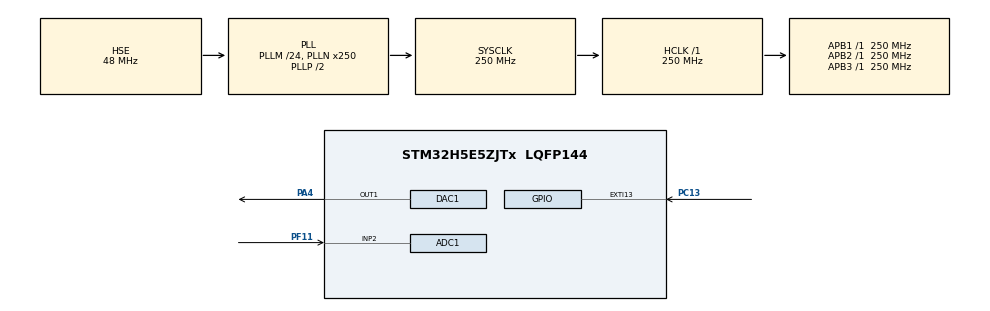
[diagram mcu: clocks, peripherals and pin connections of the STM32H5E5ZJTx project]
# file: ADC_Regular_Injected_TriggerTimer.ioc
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ADC1.Channel-0\#ChannelRegularConversion=ADC_CHANNEL_2
ADC1.ConversionDataManagement=ADC_CONVERSIONDATA_DMA_CIRCULAR
ADC1.DMAContinuousRequests=ENABLE
ADC1.EnableAnalogWatchDog1=false
ADC1.EnableInjectedConversion=ENABLE
ADC1.ExternalTrigConv=ADC_EXTERNALTRIG_T3_TRGO
ADC1.InjMonitoredBy-1\#ChannelInjectedConversion=__NULL
ADC1.InjNumberOfConversion=1
ADC1.InjectedChannel-1\#ChannelInjectedConversion=ADC_CHANNEL_VREFINT
ADC1.InjectedOffsetNumber-1\#ChannelInjectedConversion=ADC_OFFSET_NONE
ADC1.InjectedRank-1\#ChannelInjectedConversion=1
ADC1.InjectedSamplingTime-1\#ChannelInjectedConversion=ADC_SAMPLETIME_47CYCLES_5
ADC1.NbrOfConversionFlag=1
ADC1.Overrun=ADC_OVR_DATA_OVERWRITTEN
ADC1.SamplingTime-0\#ChannelRegularConversion=ADC_SAMPLETIME_247CYCLES_5
ADC1.master=1
BOOTPATH.BootPathName=LEGACY
BOOTPATH.UserSelectedBootPath=LEGACY
CORTEX_M33_NS.userName=CORTEX_M33
DAC1.DAC_Channel-DAC_OUT1=DAC_CHANNEL_1
DAC1.DAC_HighFrequency=DAC_HIGH_FREQUENCY_INTERFACE_MODE_ABOVE_160MHZ
DAC1.DAC_HoldTime-DAC_OUT1=10
DAC1.DAC_RefreshTime-DAC_OUT1=5
DAC1.DAC_SampleAndHold-DAC_OUT1=DAC_SAMPLEANDHOLD_ENABLE
DAC1.DAC_SampleTime-DAC_OUT1=20
GPDMA1.CIRCULARMODE_GPDMACH0=ENABLE
GPDMA1.DESTDATAWIDTH_GPDMACH0=DMA_DEST_DATAWIDTH_HALFWORD
GPDMA1.DESTINC_GPDMACH0=DMA_DINC_INCREMENTED
GPDMA1.IPHANDLE_GPDMACH0-SIMPLEREQUEST_GPDMACH0=__NULL
GPDMA1.PRIORITY_LL_CIRCULAR_GPDMACH0=DMA_LOW_PRIORITY_HIGH_WEIGHT
GPDMA1.REQUEST_GPDMACH0=GPDMA1_REQUEST_ADC1
GPDMA1.SRCDATAWIDTH_GPDMACH0=DMA_SRC_DATAWIDTH_HALFWORD
Mcu.Family=STM32H5
Mcu.Name=STM32H5E5ZJTx
Mcu.Package=LQFP144
NVIC.ADC1_IRQn=true\:0\:0\:false\:false\:true\:true\:true\:true
NVIC.EXTI13_IRQn=true\:0\:0\:false\:false\:true\:true\:true\:true
NVIC.GPDMA1_Channel0_IRQn=true\:0\:0\:false\:false\:true\:false\:true\:true
NVIC.PriorityGroup=NVIC_PRIORITYGROUP_4
PA4.Signal=COMP_DAC11_group
PC13.Signal=GPXTI13
PF11.Mode=IN2-Single-Ended
PF11.Signal=ADC1_INP2
PH0-OSC_IN(PH0).Mode=HSE-External-Oscillator
PH0-OSC_IN(PH0).Signal=RCC_OSC_IN
PH1-OSC_OUT(PH1).Mode=HSE-External-Oscillator
PH1-OSC_OUT(PH1).Signal=RCC_OSC_OUT
ProjectManager.HeapSize=0x200
ProjectManager.StackSize=0x400
ProjectManager.TargetToolchain=EWARM V9.20
RCC.ADCCLKDivider=RCC_ADC_DIV2
RCC.ADCCLockSelection=RCC_ADCDACCLKSOURCE_HSI
RCC.ADCFreq_Value=16000000
RCC.AHBFreq_Value=250000000
RCC.APB1Freq_Value=250000000
RCC.APB1TimFreq_Value=250000000
RCC.APB2Freq_Value=250000000
RCC.APB2TimFreq_Value=250000000
RCC.APB3Freq_Value=250000000
RCC.CSI_VALUE=4000000
RCC.CortexFreq_Value=250000000
RCC.DACLowPowerCLockSelection=RCC_DACLPCLKSOURCE_LSI
RCC.EPOD_VALUE=48000000
RCC.HCLKFreq_Value=250000000
RCC.HSE_VALUE=48000000
RCC.HSI48_VALUE=48000000
RCC.HSI_VALUE=64000000
RCC.LSE_VALUE=32768
RCC.LSIRC_VALUE=32000
RCC.PLLFRACN=0
RCC.PLLM=24
RCC.PLLN=250
RCC.PLLSourceVirtual=RCC_PLL1_SOURCE_HSE
RCC.SYSCLKFreq_VALUE=250000000
RCC.SYSCLKSource=RCC_SYSCLKSOURCE_PLLCLK
RCC.USBFreq_Value=258000000
RCC.VCOOutputFreq_Value=500000000
SH.COMP_DAC11_group.0=DAC1_OUT1,DAC_OUT1
TIM3.PeriodNoDither=PERIOD_VALUE
TIM3.Prescaler=PRESCALER_VALUE
TIM3.TIM_MasterOutputTrigger=TIM_TRGO_UPDATE
VP_ADC1_Vref_Input.Mode=IN-Vrefint
VP_BOOTPATH_VS_BOOTPATH.Mode=BP_Activate
VP_CORTEX_M33_NS_VS_Hclk.Mode=Hclk_Mode
VP_GPDMA1_VS_GPDMACH0.Mode=SIMPLEREQUEST_GPDMACH0
VP_ICACHE_VS_ICACHE.Mode=DefaultMode
VP_PWR_VS_LPOM.Mode=PowerOptimisation
VP_PWR_VS_SECSignals.Mode=Security/Privilege
VP_TIM3_VS_ClockSourceINT.Mode=Internal
board=custom

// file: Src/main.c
/* USER CODE BEGIN Header */
/**
  ******************************************************************************
  * @file           : main.c
  * @brief          : Main program body
  ******************************************************************************
  * @attention
  *
  * Copyright (c) 2025 STMicroelectronics.
  * All rights reserved.
  *
  * This software is licensed under terms that can be found in the LICENSE file
  * in the root directory of this software component.
  * If no LICENSE file comes with this software, it is provided AS-IS.
  *
  ******************************************************************************
  */
/* USER CODE END Header */
#include "main.h"

/* USER CODE BEGIN PD */
#define RANGE_12BITS                   ((uint32_t) 4095)    /* Max digital value with a full range of 12 bits */

/* ADC parameters */
#define ADCCONVERTEDVALUES_BUFFER_SIZE ((uint32_t)   32)    /* Size of array containing ADC converted values, aligned on cache line size */
/* USER CODE END PD */

ADC_HandleTypeDef hadc1;
DMA_NodeTypeDef Node_GPDMA1_Channel0;
DMA_QListTypeDef List_GPDMA1_Channel0;
DMA_HandleTypeDef handle_GPDMA1_Channel0;

DAC_HandleTypeDef hdac1;

TIM_HandleTypeDef htim3;

/* USER CODE BEGIN PV */

/* Variable containing ADC conversions results */
ALIGN_32BYTES(__IO uint16_t   aADCxConvertedValues[ADCCONVERTEDVALUES_BUFFER_SIZE]); /* ADC conversion results table of regular group, channel on rank1 */
__IO uint16_t   uhADCxConvertedValue_Injected;                        /* ADC conversion result of injected group, channel on rank1 */

uint16_t        uhADCxConvertedValue_Regular_Avg_half1;  /* Average of the 1st half of ADC conversion results table of regular group, channel on rank1 */
uint16_t        uhADCxConvertedValue_Regular_Avg_half2;  /* Average of the 2nd half of ADC conversion results table of regular group, channel on rank1 */
uint16_t*       puhADCxConvertedValue_Regular_Avg;       /* Pointer to the average of the 1st or 2nd half of ADC conversion results table of regular group, channel on rank1 */

/* Variables to manage push button on board: interface between ExtLine interruption and main program */
__IO uint8_t    ubUserButtonClickEvent = RESET;  /* Event detection: Set after User Button interrupt */

/* USER CODE END PV */

void SystemClock_Config(void);
static void MX_GPIO_Init(void);
static void MX_GPDMA1_Init(void);
static void MX_ICACHE_Init(void);
static void MX_ADC1_Init(void);
static void MX_TIM3_Init(void);
static void MX_DAC1_Init(void);
/* USER CODE BEGIN PFP */
static void WaveformVoltageGenerationForTest_Config(void);
static void WaveformVoltageGenerationForTest_Update(void);
/* USER CODE END PFP */

int main(void)
{

  /* MCU Configuration--------------------------------------------------------*/

  /* Reset of all peripherals, Initializes the Flash interface and the Systick. */
  HAL_Init();

  /* Configure the system clock */
  SystemClock_Config();

  /* USER CODE BEGIN SysInit */
  /* Initialize LED on board */
  BSP_LED_Init(LED_GREEN);
  BSP_LED_Init(LED_RED);

  /* USER CODE END SysInit */

  /* Initialize all configured peripherals */
  MX_GPIO_Init();
  MX_GPDMA1_Init();
  MX_ICACHE_Init();
  MX_ADC1_Init();
  MX_TIM3_Init();
  MX_DAC1_Init();
  /* USER CODE BEGIN 2 */

  /* Perform ADC calibration */
  if (HAL_ADCEx_Calibration_Start(&hadc1, ADC_SINGLE_ENDED) != HAL_OK)
  {
    /* Calibration Error */
    Error_Handler();
  }

  /* WAVEFORM_VOLTAGE_GENERATION_FOR_TEST */

  WaveformVoltageGenerationForTest_Config();

  /* Timer enable */
  if (HAL_TIM_Base_Start(&htim3) != HAL_OK)
  {
    /* Counter Enable Error */
    Error_Handler();
  }

    /*## Start ADC conversions #################################################*/

  /* Start ADC conversion on regular group with transfer by DMA */
  if (HAL_ADC_Start_DMA(&hadc1,
                        (uint32_t *)aADCxConvertedValues,
                        ADCCONVERTEDVALUES_BUFFER_SIZE
                       ) != HAL_OK)
  {
    /* Start Error */
    Error_Handler();
  }

  /* USER CODE END 2 */

  /* Infinite loop */
  /* USER CODE BEGIN WHILE */
  while (1)
  {
    /* Wait for event on push button to perform following actions */
    while ((ubUserButtonClickEvent) == RESET)
    {
    }
    /* Reset variable for next loop iteration */
    ubUserButtonClickEvent = RESET;

    /* Start ADC conversion on injected group */
    if (HAL_ADCEx_InjectedStart_IT(&hadc1) != HAL_OK)
    {
      /* Start Conversation Error */
      Error_Handler();
    }

    /* Modifies the voltage level incrementally from 0V to Vdda at each call. */
    /* Circular waveform of ramp: When the maximum level is reaches,          */
    /* restart from 0V.                                                       */
    WaveformVoltageGenerationForTest_Update();

    /* Wait for acquisition time of ADC samples on regular and injected       */
    /* groups:                                                                */
    /* wait time to let a full 1/2 buffer of regular group to be filled with  */
    /* new conversion values (in ms)      */
    HAL_Delay(100);

    /* Turn-on/off LED_GREEN in function of ADC conversion result */
    /* - Turn-off if voltage measured by injected group is below voltage      */
    /*   measured by regular group (average of results table)                 */
    /* - Turn-off if voltage measured by injected group is above voltage      */
    /*   measured by regular group (average of results table)                 */

    /* Variables of conversions results are updated into ADC conversions      */
    /* interrupt callback.                                                    */

    if (uhADCxConvertedValue_Injected < *puhADCxConvertedValue_Regular_Avg)
    {
      BSP_LED_Off(LED_GREEN);
    }
    else
    {
      BSP_LED_On(LED_GREEN);
    }

    /* USER CODE END WHILE */

  }
}

void SystemClock_Config(void)
{
  RCC_OscInitTypeDef RCC_OscInitStruct = {0};
  RCC_ClkInitTypeDef RCC_ClkInitStruct = {0};

  /** Configure the main internal regulator output voltage
  */
  __HAL_PWR_VOLTAGESCALING_CONFIG(PWR_REGULATOR_VOLTAGE_SCALE0);

  while(!__HAL_PWR_GET_FLAG(PWR_FLAG_VOSRDY)) {}

  /** Initializes the RCC Oscillators according to the specified parameters
  * in the RCC_OscInitTypeDef structure.
  */
  RCC_OscInitStruct.OscillatorType = RCC_OSCILLATORTYPE_HSI|RCC_OSCILLATORTYPE_LSI
                              |RCC_OSCILLATORTYPE_HSE;
  RCC_OscInitStruct.HSEState = RCC_HSE_ON;
  RCC_OscInitStruct.HSIState = RCC_HSI_ON;
  RCC_OscInitStruct.HSIDiv = RCC_HSI_DIV2;
  RCC_OscInitStruct.HSICalibrationValue = RCC_HSICALIBRATION_DEFAULT;
  RCC_OscInitStruct.LSIState = RCC_LSI_ON;
  RCC_OscInitStruct.PLL.PLLState = RCC_PLL_ON;
  RCC_OscInitStruct.PLL.PLLSource = RCC_PLL1_SOURCE_HSE;
  RCC_OscInitStruct.PLL.PLLM = 24;
  RCC_OscInitStruct.PLL.PLLN = 250;
  RCC_OscInitStruct.PLL.PLLP = 2;
  RCC_OscInitStruct.PLL.PLLQ = 2;
  RCC_OscInitStruct.PLL.PLLR = 2;
  RCC_OscInitStruct.PLL.PLLRGE = RCC_PLL1_VCIRANGE_1;
  RCC_OscInitStruct.PLL.PLLVCOSEL = RCC_PLL1_VCORANGE_WIDE;
  RCC_OscInitStruct.PLL.PLLFRACN = 0;
  if (HAL_RCC_OscConfig(&RCC_OscInitStruct) != HAL_OK)
  {
    Error_Handler();
  }

  /** Initializes the CPU, AHB and APB buses clocks
  */
  RCC_ClkInitStruct.ClockType = RCC_CLOCKTYPE_HCLK|RCC_CLOCKTYPE_SYSCLK
                              |RCC_CLOCKTYPE_PCLK1|RCC_CLOCKTYPE_PCLK2
                              |RCC_CLOCKTYPE_PCLK3;
  RCC_ClkInitStruct.SYSCLKSource = RCC_SYSCLKSOURCE_PLLCLK;
  RCC_ClkInitStruct.AHBCLKDivider = RCC_SYSCLK_DIV1;
  RCC_ClkInitStruct.APB1CLKDivider = RCC_HCLK_DIV1;
  RCC_ClkInitStruct.APB2CLKDivider = RCC_HCLK_DIV1;
  RCC_ClkInitStruct.APB3CLKDivider = RCC_HCLK_DIV1;

  if (HAL_RCC_ClockConfig(&RCC_ClkInitStruct, FLASH_LATENCY_5) != HAL_OK)
  {
    Error_Handler();
  }

  /** Configure the programming delay
  */
  __HAL_FLASH_SET_PROGRAM_DELAY(FLASH_PROGRAMMING_DELAY_2);
}

static void MX_ADC1_Init(void)
{

  ADC_ChannelConfTypeDef sConfig = {0};
  ADC_InjectionConfTypeDef sConfigInjected = {0};

  /** Common config
  */
  hadc1.Instance = ADC1;
  hadc1.Init.ClockPrescaler = ADC_CLOCK_ASYNC_DIV1;
  hadc1.Init.Resolution = ADC_RESOLUTION_12B;
  hadc1.Init.DataAlign = ADC_DATAALIGN_RIGHT;
  hadc1.Init.ScanConvMode = ADC_SCAN_DISABLE;
  hadc1.Init.EOCSelection = ADC_EOC_SINGLE_CONV;
  hadc1.Init.LowPowerAutoWait = DISABLE;
  hadc1.Init.ContinuousConvMode = DISABLE;
  hadc1.Init.NbrOfConversion = 1;
  hadc1.Init.DiscontinuousConvMode = DISABLE;
  hadc1.Init.ExternalTrigConv = ADC_EXTERNALTRIG_T3_TRGO;
  hadc1.Init.ExternalTrigConvEdge = ADC_EXTERNALTRIGCONVEDGE_RISING;
  hadc1.Init.DMAContinuousRequests = ENABLE;
  hadc1.Init.SamplingMode = ADC_SAMPLING_MODE_NORMAL;
  hadc1.Init.Overrun = ADC_OVR_DATA_OVERWRITTEN;
  hadc1.Init.OversamplingMode = DISABLE;
  if (HAL_ADC_Init(&hadc1) != HAL_OK)
  {
    Error_Handler();
  }

  /** Disable Injected Queue
  */
  HAL_ADCEx_DisableInjectedQueue(&hadc1);

  /** Configure Regular Channel
  */
  sConfig.Channel = ADC_CHANNEL_2;
  sConfig.Rank = ADC_REGULAR_RANK_1;
  sConfig.SamplingTime = ADC_SAMPLETIME_247CYCLES_5;
  sConfig.SingleDiff = ADC_SINGLE_ENDED;
  sConfig.OffsetNumber = ADC_OFFSET_NONE;
  sConfig.Offset = 0;
  if (HAL_ADC_ConfigChannel(&hadc1, &sConfig) != HAL_OK)
  {
    Error_Handler();
  }

  /** Configure Injected Channel
  */
  sConfigInjected.InjectedChannel = ADC_CHANNEL_VREFINT;
  sConfigInjected.InjectedRank = ADC_INJECTED_RANK_1;
  sConfigInjected.InjectedSamplingTime = ADC_SAMPLETIME_47CYCLES_5;
  sConfigInjected.InjectedSingleDiff = ADC_SINGLE_ENDED;
  sConfigInjected.InjectedOffsetNumber = ADC_OFFSET_NONE;
  sConfigInjected.InjectedOffset = 0;
  sConfigInjected.InjectedNbrOfConversion = 1;
  sConfigInjected.InjectedDiscontinuousConvMode = DISABLE;
  sConfigInjected.AutoInjectedConv = DISABLE;
  sConfigInjected.QueueInjectedContext = DISABLE;
  sConfigInjected.ExternalTrigInjecConv = ADC_INJECTED_SOFTWARE_START;
  sConfigInjected.ExternalTrigInjecConvEdge = ADC_EXTERNALTRIGINJECCONV_EDGE_NONE;
  sConfigInjected.InjecOversamplingMode = DISABLE;
  if (HAL_ADCEx_InjectedConfigChannel(&hadc1, &sConfigInjected) != HAL_OK)
  {
    Error_Handler();
  }

}

static void MX_DAC1_Init(void)
{

  DAC_ChannelConfTypeDef sConfig = {0};

  /** DAC Initialization
  */
  hdac1.Instance = DAC1;
  if (HAL_DAC_Init(&hdac1) != HAL_OK)
  {
    Error_Handler();
  }

  /** DAC channel OUT1 config
  */
  sConfig.DAC_HighFrequency = DAC_HIGH_FREQUENCY_INTERFACE_MODE_ABOVE_160MHZ;
  sConfig.DAC_DMADoubleDataMode = DISABLE;
  sConfig.DAC_SignedFormat = DISABLE;
  sConfig.DAC_SampleAndHold = DAC_SAMPLEANDHOLD_ENABLE;
  sConfig.DAC_Trigger = DAC_TRIGGER_NONE;
  sConfig.DAC_OutputBuffer = DAC_OUTPUTBUFFER_ENABLE;
  sConfig.DAC_ConnectOnChipPeripheral = DAC_CHIPCONNECT_EXTERNAL;
  sConfig.DAC_UserTrimming = DAC_TRIMMING_FACTORY;
  sConfig.DAC_SampleAndHoldConfig.DAC_SampleTime = 20;
  sConfig.DAC_SampleAndHoldConfig.DAC_HoldTime = 10;
  sConfig.DAC_SampleAndHoldConfig.DAC_RefreshTime = 5;
  if (HAL_DAC_ConfigChannel(&hdac1, &sConfig, DAC_CHANNEL_1) != HAL_OK)
  {
    Error_Handler();
  }

}

static void MX_GPDMA1_Init(void)
{

  /* Peripheral clock enable */
  __HAL_RCC_GPDMA1_CLK_ENABLE();

  /* GPDMA1 interrupt Init */
    HAL_NVIC_SetPriority(GPDMA1_Channel0_IRQn, 0, 0);
    HAL_NVIC_EnableIRQ(GPDMA1_Channel0_IRQn);

}

static void MX_ICACHE_Init(void)
{

  /** Enable instruction cache (default 2-ways set associative cache)
  */
  if (HAL_ICACHE_Enable() != HAL_OK)
  {
    Error_Handler();
  }

}

static void MX_TIM3_Init(void)
{

  TIM_ClockConfigTypeDef sClockSourceConfig = {0};
  TIM_MasterConfigTypeDef sMasterConfig = {0};

  htim3.Instance = TIM3;
  htim3.Init.Prescaler = PRESCALER_VALUE;
  htim3.Init.CounterMode = TIM_COUNTERMODE_UP;
  htim3.Init.Period = PERIOD_VALUE;
  htim3.Init.ClockDivision = TIM_CLOCKDIVISION_DIV1;
  htim3.Init.AutoReloadPreload = TIM_AUTORELOAD_PRELOAD_DISABLE;
  if (HAL_TIM_Base_Init(&htim3) != HAL_OK)
  {
    Error_Handler();
  }
  sClockSourceConfig.ClockSource = TIM_CLOCKSOURCE_INTERNAL;
  if (HAL_TIM_ConfigClockSource(&htim3, &sClockSourceConfig) != HAL_OK)
  {
    Error_Handler();
  }
  sMasterConfig.MasterOutputTrigger = TIM_TRGO_UPDATE;
  sMasterConfig.MasterSlaveMode = TIM_MASTERSLAVEMODE_DISABLE;
  if (HAL_TIMEx_MasterConfigSynchronization(&htim3, &sMasterConfig) != HAL_OK)
  {
    Error_Handler();
  }

}

static void MX_GPIO_Init(void)
{
  GPIO_InitTypeDef GPIO_InitStruct = {0};

  /* GPIO Ports Clock Enable */
  __HAL_RCC_GPIOC_CLK_ENABLE();
  __HAL_RCC_GPIOH_CLK_ENABLE();

  /*Configure GPIO pin : PC13 */
  GPIO_InitStruct.Pin = GPIO_PIN_13;
  GPIO_InitStruct.Mode = GPIO_MODE_IT_RISING;
  GPIO_InitStruct.Pull = GPIO_NOPULL;
  HAL_GPIO_Init(GPIOC, &GPIO_InitStruct);

  /* EXTI interrupt init*/
  HAL_NVIC_SetPriority(EXTI13_IRQn, 0, 0);
  HAL_NVIC_EnableIRQ(EXTI13_IRQn);

}

/* USER CODE BEGIN 4 */

/**
  * @brief  For this example, generate a waveform voltage on a spare DAC
  *         channel, so user has just to connect a wire between DAC channel
  *         (pin PA.04) and ADC channel (pin PF.11) to run this example.
  *         (this prevents the user from resorting to an external signal generator)
  *         This function configures the DAC and generates a constant voltage of Vdda/2.
  *         To modify the voltage level, use function "WaveformVoltageGenerationForTest_Update"
  * @param  None
  * @retval None
  */
static void WaveformVoltageGenerationForTest_Config(void)
{

  /*## Enable peripherals ####################################################*/

  /* Set DAC Channel data register: channel corresponding to ADC channel CHANNELa */
  /* Set DAC output to 1/2 of full range (4095 <=> Vdda=3.3V): 2048 <=> 1.65V */
  if (HAL_DAC_SetValue(&hdac1, DAC_CHANNEL_1, DAC_ALIGN_12B_R, (RANGE_12BITS/2)) != HAL_OK)
  {
    /* Setting value Error */
    Error_Handler();
  }

  /* Enable DAC Channel: channel corresponding to ADC channel CHANNELa */
  if (HAL_DAC_Start(&hdac1, DAC_CHANNEL_1) != HAL_OK)
  {
    /* Start Error */
    Error_Handler();
  }

}

/**
  * @brief  For this example, generate a waveform voltage on a spare DAC
  *         channel, so user has just to connect a wire between DAC channel
  *         (pin PA.04) and ADC channel (pin PF.11) to run this example.
  *         (this prevents the user from resorting to an external signal generator)
  *         This function modifies the voltage level  from 0V to Vdda in 4 steps,
  *         incrementally at each function call.
  *         Circular waveform of ramp: When the maximum level is reaches,
  *         restart from 0V.
  * @param  None
  * @retval None
  */
static void WaveformVoltageGenerationForTest_Update(void)
{
  static uint8_t ub_dac_steps_count = 0;      /* Count number of clicks: Incremented after User Button interrupt */

  /* Set DAC voltage on channel corresponding to ADCy_CHANNELa              */
  /* in function of user button clicks count.                               */
  /* Set DAC output on 5 voltage levels, successively to:                   */
  /*  - minimum of full range (0 <=> ground 0V)                             */
  /*  - 1/4 of full range (4095 <=> Vdda=3.3V): 1023 <=> 0.825V             */
  /*  - 1/2 of full range (4095 <=> Vdda=3.3V): 2048 <=> 1.65V              */
  /*  - 3/4 of full range (4095 <=> Vdda=3.3V): 3071 <=> 2.475V             */
  /*  - maximum of full range (4095 <=> Vdda=3.3V)                          */
  if (HAL_DAC_SetValue(&hdac1,
                       DAC_CHANNEL_1,
                       DAC_ALIGN_12B_R,
                       ((RANGE_12BITS * ub_dac_steps_count) / 4)
                      ) != HAL_OK)
  {
    /* Start Error */
    Error_Handler();
  }

  /* Wait for voltage settling time */
  HAL_Delay(1);

  /* Manage ub_dac_steps_count to increment it in 4 steps and circularly.   */
  if (ub_dac_steps_count < 4)
  {
    ub_dac_steps_count++;
  }
  else
  {
    ub_dac_steps_count = 0;
  }

}

/**
  * @brief EXTI line detection callbacks
  * @param GPIO_Pin: Specifies the pins connected EXTI line
  * @retval None
  */
void HAL_GPIO_EXTI_Rising_Callback(uint16_t GPIO_Pin)
{
  if (GPIO_Pin == BUTTON_USER_PIN)
  {
    /* Set variable to report push button event to main program */
    ubUserButtonClickEvent = SET;
  }

}

/**
  * @brief  Conversion complete callback in non blocking mode
  * @param  AdcHandle : ADC handle
  * @note   This example shows a simple way to report end of conversion
  *         and get conversion result. You can add your own implementation.
  * @retval None
  */
void HAL_ADC_ConvCpltCallback(ADC_HandleTypeDef *AdcHandle)
{
  uint32_t tmp_index = 0;
  uint32_t tmp_average = 0; /* Variable 32 bits for intermediate processing */

  /* Process average of the 2nd half of the buffer */
  for (tmp_index = 0; tmp_index < (ADCCONVERTEDVALUES_BUFFER_SIZE/2); tmp_index++)
  {
    tmp_average += aADCxConvertedValues[tmp_index + (ADCCONVERTEDVALUES_BUFFER_SIZE/2)];
  }
  tmp_average /= (ADCCONVERTEDVALUES_BUFFER_SIZE/2);
  uhADCxConvertedValue_Regular_Avg_half2 = (uint16_t)tmp_average;

  /* Affect pointer to the average of the 2nd half of ADC conversion results  */
  /* table of regular group, channel on rank1.                                */
  puhADCxConvertedValue_Regular_Avg = &uhADCxConvertedValue_Regular_Avg_half2;

}

/**
  * @brief  Conversion DMA half-transfer callback in non blocking mode
  * @param  hadc: ADC handle
  * @retval None
  */
void HAL_ADC_ConvHalfCpltCallback(ADC_HandleTypeDef* hadc)
{
  uint32_t tmp_index = 0;
  uint32_t tmp_average = 0; /* Variable 32 bits for intermediate processing */

  /* Process average of the 1st half of the buffer */
  for (tmp_index = 0; tmp_index < (ADCCONVERTEDVALUES_BUFFER_SIZE/2); tmp_index++)
  {
    tmp_average += aADCxConvertedValues[tmp_index];
  }
  tmp_average /= (ADCCONVERTEDVALUES_BUFFER_SIZE/2);
  uhADCxConvertedValue_Regular_Avg_half1 = (uint16_t)tmp_average;

  /* Affect pointer to the average of the 1st half of ADC conversion results  */
  /* table of regular group, channel on rank1.                                */
  puhADCxConvertedValue_Regular_Avg = &uhADCxConvertedValue_Regular_Avg_half1;

}

/**
  * @brief  Injected conversion complete callback in non blocking mode
  * @param  hadc: ADC handle
  * @retval None
  */
void HAL_ADCEx_InjectedConvCpltCallback(ADC_HandleTypeDef* hadc)
{
  uhADCxConvertedValue_Injected = HAL_ADCEx_InjectedGetValue(hadc, ADC_INJECTED_RANK_1);
}

/**
  * @brief  Analog watchdog callback in non blocking mode.
  * @param  hadc: ADC handle
  * @retval None
  */

/**
  * @brief  ADC error callback in non blocking mode
  *        (ADC conversion with interruption or transfer by DMA)
  * @param  hadc: ADC handle
  * @retval None
  */
void HAL_ADC_ErrorCallback(ADC_HandleTypeDef *hadc)
{
  /* In case of ADC error, call main error handler */
  Error_Handler();
}

/* USER CODE END 4 */

void Error_Handler(void)
{
  /* USER CODE BEGIN Error_Handler_Debug */
  /* User can add his own implementation to report the HAL error return state */
  __disable_irq();
  /* In case of error, LED_RED is toggling at a frequency of 1Hz */
  while(1)
  {
    /* Toggle LED2 */
    BSP_LED_Toggle(LED_RED);
    HAL_Delay(500);
  }
  /* USER CODE END Error_Handler_Debug */
}
